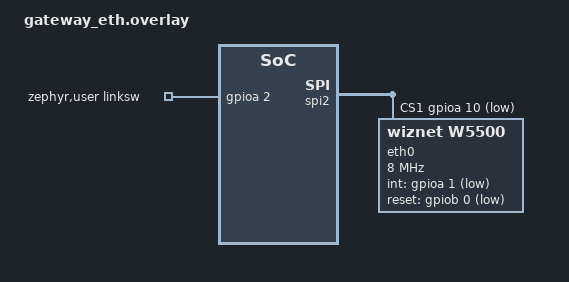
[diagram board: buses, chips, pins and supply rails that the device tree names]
/*
 * Snippet overlay: gateway_eth — 网关板 W5500 以太网
 *
 * 在基线 (手柄板) overlay 之上叠加:
 *   - chosen 增加 zephyr,ethernet
 *   - link 按键改回网关板引脚 PA2 (覆盖基线 PA10)
 *   - SPI2 cs-gpios 增加 W5500 第二路 CS (PA10), 覆盖基线单路
 *   - 新增 eth0 (W5500) 节点
 */

/ {
	chosen {
		zephyr,ethernet = &eth0;
	};

	zephyr,user {
		/* 网关板 link 按键为 PA2 (覆盖基线 PA10) */
		linksw-gpios = <&gpioa 2 GPIO_PULL_UP>;
	};
};

&spi2 {
	/* 覆盖基线: 增加 W5500 第二路 CS */
	cs-gpios = <&gpiob 12 GPIO_ACTIVE_LOW>,    /* nRF24 CS */
		   <&gpioa 10 GPIO_ACTIVE_LOW>;    /* W5500 CS */

	eth0: w5500@1 {
		compatible = "wiznet,w5500";
		reg = <0x1>;
		spi-max-frequency = <8000000>;
		int-gpios = <&gpioa 1 GPIO_ACTIVE_LOW>;
		reset-gpios = <&gpiob 0 GPIO_ACTIVE_LOW>;
		local-mac-address = [00 08 DC 01 02 03];
		status = "okay";
	};
};
